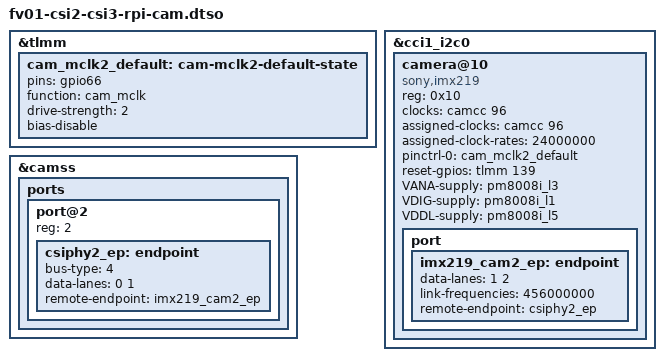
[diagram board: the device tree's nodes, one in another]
/dts-v1/;
/plugin/;

/*
 * FV01 Internal Ports 2 & 3 (22-Pin RPi CSI Camera Connectors) Overlay Template
 * Verified against Factory running.dts cam-sensor2 (CSIPHY2) and cam-sensor3 (CSIPHY3):
 * - Both connectors share CCI1 I2C0 (TLMM GPIO 73/74); assign distinct I2C addresses
 *   (e.g., 0x10 vs 0x36) or enable only one connector if two identical IMX219 modules
 *   share 0x10.
 * - CSIPHY2 (Port 2): CAM_CC_MCLK2_CLK (ID 96) on GPIO 66, RESET on GPIO 139.
 * - CSIPHY3 (Port 3): CAM_CC_MCLK3_CLK (ID 98) on GPIO 67, RESET on GPIO 79.
 */

&tlmm {
	cam_mclk2_default: cam-mclk2-default-state {
		pins = "gpio66";
		function = "cam_mclk";
		drive-strength = <2>;
		bias-disable;
	};
};

&cci1_i2c0 {
	#address-cells = <1>;
	#size-cells = <0>;

	camera@10 {
		compatible = "sony,imx219";
		reg = <0x10>;
		clocks = <&camcc 96>;
		assigned-clocks = <&camcc 96>;
		assigned-clock-rates = <24000000>;
		pinctrl-names = "default";
		pinctrl-0 = <&cam_mclk2_default>;
		reset-gpios = <&tlmm 139 0>;
		VANA-supply = <&pm8008i_l3>;
		VDIG-supply = <&pm8008i_l1>;
		VDDL-supply = <&pm8008i_l5>;

		port {
			imx219_cam2_ep: endpoint {
				data-lanes = <1 2>;
				link-frequencies = /bits/ 64 <456000000>;
				remote-endpoint = <&csiphy2_ep>;
			};
		};
	};
};

&camss {
	ports {
		#address-cells = <1>;
		#size-cells = <0>;

		port@2 {
			reg = <2>;

			csiphy2_ep: endpoint {
				bus-type = <4>;
				data-lanes = <0 1>;
				remote-endpoint = <&imx219_cam2_ep>;
			};
		};
	};
};
